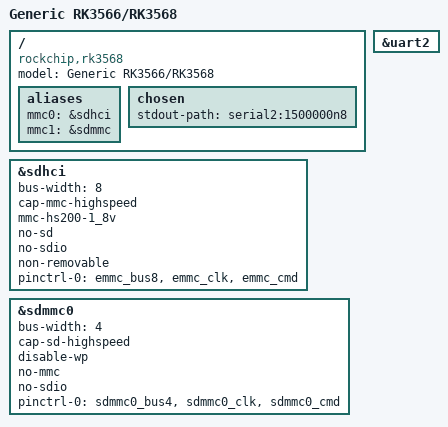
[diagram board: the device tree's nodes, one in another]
// SPDX-License-Identifier: (GPL-2.0+ OR MIT)
/*
 * Minimal generic DT for RK3566/RK3568 with eMMC and SD-card enabled
 */

/dts-v1/;
#include "rk356x.dtsi"

/ {
	model = "Generic RK3566/RK3568";
	compatible = "rockchip,rk3568";

	aliases {
		mmc0 = &sdhci;
		mmc1 = &sdmmc;
	};

	chosen {
		stdout-path = "serial2:1500000n8";
	};
};

&sdhci {
	bus-width = <8>;
	cap-mmc-highspeed;
	mmc-hs200-1_8v;
	no-sd;
	no-sdio;
	non-removable;
	pinctrl-names = "default";
	pinctrl-0 = <&emmc_bus8 &emmc_clk &emmc_cmd>;
	status = "okay";
};

&sdmmc0 {
	bus-width = <4>;
	cap-sd-highspeed;
	disable-wp;
	no-mmc;
	no-sdio;
	pinctrl-names = "default";
	pinctrl-0 = <&sdmmc0_bus4 &sdmmc0_clk &sdmmc0_cmd>;
	status = "okay";
};

&uart2 {
	status = "okay";
};
